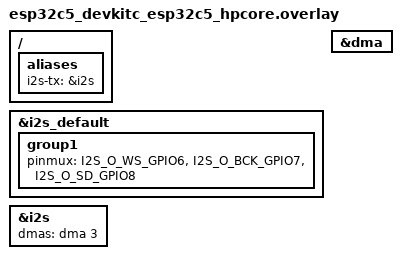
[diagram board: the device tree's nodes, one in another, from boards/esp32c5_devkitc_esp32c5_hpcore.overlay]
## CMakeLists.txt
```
# SPDX-License-Identifier: Apache-2.0

cmake_minimum_required(VERSION 3.20.0)
find_package(Zephyr REQUIRED HINTS $ENV{ZEPHYR_BASE})
project(app_more_services10)

zephyr_syscall_header(${CMAKE_CURRENT_SOURCE_DIR}/src/svc.h)

target_sources(app PRIVATE src/main.c src/svc.c)
```

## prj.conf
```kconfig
CONFIG_USERSPACE=y
CONFIG_APPLICATION_DEFINED_SYSCALL=y

CONFIG_I2S=y
CONFIG_DMA=y

CONFIG_LOG=y
CONFIG_LOG_MODE_MINIMAL=y
CONFIG_THREAD_NAME=y

CONFIG_MAIN_STACK_SIZE=4096
```

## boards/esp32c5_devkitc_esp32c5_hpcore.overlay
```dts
/*
 * Copyright (c) 2026 Espressif Systems (Shanghai) Co., Ltd.
 *
 * SPDX-License-Identifier: Apache-2.0
 */

/* I2S TX: WS on GPIO6, BCK on GPIO7, SD on GPIO8, streamed over GDMA. */
/ {
	aliases {
		i2s-tx = &i2s;
	};
};

&i2s_default {
	group1 {
		pinmux = <I2S_O_WS_GPIO6>,
			 <I2S_O_BCK_GPIO7>,
			 <I2S_O_SD_GPIO8>;
	};
};

&i2s {
	status = "okay";
	dmas = <&dma 3>;
	dma-names = "tx";
};

&dma {
	status = "okay";
};
```

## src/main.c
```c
/*
 * Copyright (c) 2026 Espressif Systems (Shanghai) Co., Ltd.
 *
 * SPDX-License-Identifier: Apache-2.0
 */

/*
 * An app playing audio through an I2S service from user mode. The platform owns
 * the I2S controller, its DMA, and the transmit slab; the app only generates PCM
 * samples and hands them over. Here it synthesizes a short sine-like tone and
 * streams several blocks, never touching the I2S device or its kernel objects.
 */

#include "svc.h"

#include <zephyr/kernel.h>
#include <zephyr/sys/printk.h>

#define STACK_SIZE  4096
#define APP_PRIO    5
#define SAMPLES     256

K_THREAD_STACK_DEFINE(app_stack, STACK_SIZE);
static struct k_thread app_thread;

/* A tiny triangle wave: cheap to compute in user mode, no math library. */
static void fill_tone(int16_t *buf, int n_frames, int step)
{
	int16_t v = 0;

	for (int i = 0; i < n_frames; i++) {
		v = (int16_t)((i * step) & 0x3fff);
		buf[2 * i] = v;       /* left  */
		buf[2 * i + 1] = v;   /* right */
	}
}

static void app_entry(void *p1, void *p2, void *p3)
{
	ARG_UNUSED(p1); ARG_UNUSED(p2); ARG_UNUSED(p3);

	int16_t pcm[SAMPLES * 2];

	for (int round = 0; round < 4; round++) {
		fill_tone(pcm, SAMPLES, 64 * (round + 1));

		int rc = svc_audio_play((const uint8_t *)pcm, sizeof(pcm));

		printk("  [app] round %d: played %d bytes (rc=%d)\n",
		       round, (int)sizeof(pcm), rc);
	}

	printk("  [app] done - streamed PCM through I2S service\n");
}

int main(void)
{
	printk("\n*** more services 10: I2S audio (C6) ***\n");

	int rc = svc_audio_install();

	printk("  [platform] i2s configure rc=%d\n", rc);

	k_tid_t t = k_thread_create(&app_thread, app_stack, STACK_SIZE, app_entry,
				    NULL, NULL, NULL, APP_PRIO, K_USER, K_FOREVER);

	k_thread_start(t);
	k_thread_join(t, K_FOREVER);

	printk("\n*** done ***\n");
	return 0;
}
```

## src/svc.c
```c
/*
 * Copyright (c) 2026 Espressif Systems (Shanghai) Co., Ltd.
 *
 * SPDX-License-Identifier: Apache-2.0
 */

#include "svc.h"

#include <zephyr/kernel.h>
#include <zephyr/device.h>
#include <zephyr/drivers/i2s.h>
#include <zephyr/internal/syscall_handler.h>
#include <string.h>
#include <errno.h>

#define BLOCK_SIZE  1024
#define NUM_BLOCKS  4

/* The platform owns the I2S controller and the transmit memory slab. */
static const struct device *const i2s_dev = DEVICE_DT_GET(DT_ALIAS(i2s_tx));
K_MEM_SLAB_DEFINE_STATIC(tx_slab, BLOCK_SIZE, NUM_BLOCKS, 4);

static int queued;
static bool started;

int svc_audio_install(void)
{
	if (!device_is_ready(i2s_dev)) {
		return -ENODEV;
	}

	struct i2s_config cfg = {
		.word_size = 16U,
		.channels = 2U,
		.format = I2S_FMT_DATA_FORMAT_I2S,
		.frame_clk_freq = 44100,
		.block_size = BLOCK_SIZE,
		.timeout = 2000,
		.options = I2S_OPT_FRAME_CLK_CONTROLLER | I2S_OPT_BIT_CLK_CONTROLLER,
		.mem_slab = &tx_slab,
	};

	return i2s_configure(i2s_dev, I2S_DIR_TX, &cfg);
}

int z_impl_svc_audio_play(const uint8_t *pcm, size_t len)
{
	void *block;
	int rc;

	if (!device_is_ready(i2s_dev) || len == 0U || len > BLOCK_SIZE) {
		return -EINVAL;
	}

	rc = k_mem_slab_alloc(&tx_slab, &block, K_MSEC(200));
	if (rc != 0) {
		return rc;
	}

	memcpy(block, pcm, len);
	if (len < BLOCK_SIZE) {
		memset((uint8_t *)block + len, 0, BLOCK_SIZE - len);
	}

	rc = i2s_write(i2s_dev, block, BLOCK_SIZE);
	if (rc != 0) {
		k_mem_slab_free(&tx_slab, block);
		return rc;
	}

	/* Build a small runway before starting so the DMA does not underrun. */
	queued++;
	if (!started && queued >= 2) {
		rc = i2s_trigger(i2s_dev, I2S_DIR_TX, I2S_TRIGGER_START);
		if (rc != 0) {
			return rc;
		}
		started = true;
	}

	return (int)len;
}

#ifdef CONFIG_USERSPACE
static inline int z_vrfy_svc_audio_play(const uint8_t *pcm, size_t len)
{
	if (len == 0U || len > BLOCK_SIZE) {
		return -EINVAL;
	}
	K_OOPS(K_SYSCALL_MEMORY_READ(pcm, len));
	return z_impl_svc_audio_play(pcm, len);
}
#include <zephyr/syscalls/svc_audio_play_mrsh.c>
#endif
```

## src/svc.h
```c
/*
 * Copyright (c) 2026 Espressif Systems (Shanghai) Co., Ltd.
 *
 * SPDX-License-Identifier: Apache-2.0
 */

#ifndef APP_MORE_SERVICES10_SVC_H_
#define APP_MORE_SERVICES10_SVC_H_

#include <zephyr/kernel.h>

/*
 * A tenth batch: an I2S audio-output service. The platform owns the I2S
 * controller, its DMA, and the transmit memory slab; the app simply hands raw
 * PCM samples to be played. The supervisor copies the app bytes into a slab
 * block and streams them, so none of the I2S kernel objects are exposed to user
 * mode.
 *
 *   svc_audio_play - queue @len bytes of PCM (16-bit stereo) for playback.
 */

/* Scoped: queue @len bytes of PCM for I2S playback. Returns bytes accepted. */
__syscall int svc_audio_play(const uint8_t *pcm, size_t len);

/* Supervisor-only: configure I2S TX before launching the app. */
int svc_audio_install(void);

#include <zephyr/syscalls/svc.h>

#endif /* APP_MORE_SERVICES10_SVC_H_ */
```
